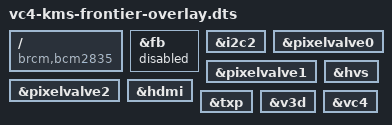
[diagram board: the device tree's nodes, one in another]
/dts-v1/;
/plugin/;

/ {
    compatible = "brcm,bcm2835";

    /*
     * Bring up the native VC4 display component graph used by the Pi 3:
     * HVS, all three pixel valves, HDMI, TXP, V3D, and the VC4 DRM master.
     * The firmware framebuffer is disabled so any CRTC, connector, mode, or
     * fbdev object observed by the witness must come from Linux VC4 KMS.
     * The probe also snapshots the live HVS channel and active display list,
     * keeping topology success distinct from successful native scanout.
     *
     * Legacy modeset, inherited and explicit DRM-master handoff, page-flip,
     * and atomic primary-plane witnesses all use this exact graph.  Keeping
     * one shared topology prevents a later gate from passing only because a
     * test-specific device-tree variant silently enabled different hardware.
     *
     * This intentionally follows the official vc4-kms-v3d overlay topology
     * but leaves optional VEC/DSI/DPI outputs disabled.  It is the smallest
     * physical-scanout frontier above the already-proven HVS/TXP/V3D render
     * topology.
     */
    fragment@0 {
        target = <&fb>;
        __overlay__ {
            status = "disabled";
        };
    };

    fragment@1 {
        target = <&i2c2>;
        __overlay__ {
            status = "okay";
        };
    };

    fragment@2 {
        target = <&pixelvalve0>;
        __overlay__ {
            status = "okay";
        };
    };

    fragment@3 {
        target = <&pixelvalve1>;
        __overlay__ {
            status = "okay";
        };
    };

    fragment@4 {
        target = <&pixelvalve2>;
        __overlay__ {
            status = "okay";
        };
    };

    fragment@5 {
        target = <&hvs>;
        __overlay__ {
            status = "okay";
        };
    };

    fragment@6 {
        target = <&hdmi>;
        __overlay__ {
            status = "okay";
        };
    };

    fragment@7 {
        target = <&txp>;
        __overlay__ {
            status = "okay";
        };
    };

    fragment@8 {
        target = <&v3d>;
        __overlay__ {
            status = "okay";
        };
    };

    fragment@9 {
        target = <&vc4>;
        __overlay__ {
            status = "okay";
        };
    };
};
